VERSION ""

NS_ :

BS_:
BU_: SENSOR_MODULE
BO_ 2147485696 PORT_SONAR: 8 SENSOR_MODULE
   SG_ PORT_SONAR_HEIGHT : 1|16@0+ (1,0) [0|6000] "mm" SENSOR_MODULE

BO_ 2147485697 STARBOARD_SONAR: 8 SENSOR_MODULE
   SG_ STARBOARD_SONAR_HEIGHT : 1|16@0+ (1,0) [0|6000] "mm" SENSOR_MODULE

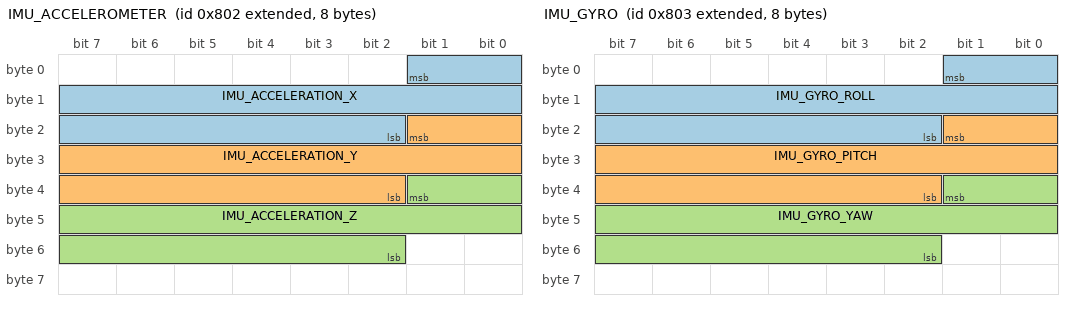
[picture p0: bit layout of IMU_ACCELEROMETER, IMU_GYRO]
BO_ 2147485698 IMU_ACCELEROMETER: 8 SENSOR_MODULE
   SG_ IMU_ACCELERATION_X : 1|16@0- (1,0) [-40|40] "" SENSOR_MODULE
   SG_ IMU_ACCELERATION_Y : 17|16@0- (1,0) [-40|40] "" SENSOR_MODULE
   SG_ IMU_ACCELERATION_Z : 33|16@0- (1,0) [-40|40] "" SENSOR_MODULE

BO_ 2147485699 IMU_GYRO: 8 SENSOR_MODULE
   SG_ IMU_GYRO_ROLL : 1|16@0- (1,0) [-250|250] "" SENSOR_MODULE
   SG_ IMU_GYRO_PITCH : 17|16@0- (1,0) [-250|250] "" SENSOR_MODULE
   SG_ IMU_GYRO_YAW : 33|16@0- (1,0) [-250|250] "" SENSOR_MODULE

CM_ SG_ 2147485698 IMU_ACCELERATION_X "m/s^2";
CM_ SG_ 2147485698 IMU_ACCELERATION_Y "m/s^2";
CM_ SG_ 2147485698 IMU_ACCELERATION_Z "m/s^2";
CM_ SG_ 2147485698 IMU_GYRO_ROLL "deg/s";
CM_ SG_ 2147485698 IMU_GYRO_PITCH "deg/s";
CM_ SG_ 2147485698 IMU_GYRO_YAW "deg/s";
BA_DEF_ BO_ "GenMsgBackgroundColor" STRING ;
BA_DEF_ BO_ "GenMsgForegroundColor" STRING ;
BA_DEF_ BO_ "filterlabeling" INT 0 0;
BA_DEF_DEF_ "GenMsgBackgroundColor" "#ffffff";
BA_DEF_DEF_ "GenMsgForegroundColor" "#000000";
BA_DEF_DEF_ "filterlabeling" 1;
